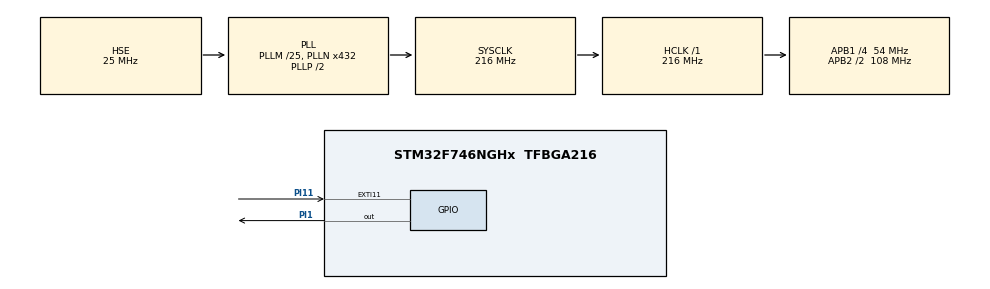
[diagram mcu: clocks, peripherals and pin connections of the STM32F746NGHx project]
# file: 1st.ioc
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Mcu.Family=STM32F7
Mcu.Name=STM32F746NGHx
Mcu.Package=TFBGA216
NVIC.EXTI15_10_IRQn=true\:3\:3\:true\:false\:true\:true\:true
NVIC.PriorityGroup=NVIC_PRIORITYGROUP_2
NVIC.TIM2_IRQn=true\:0\:0\:false\:false\:true\:true\:true
PA13.Mode=Trace_Asynchronous_SW
PA13.Signal=SYS_JTMS-SWDIO
PA14.Mode=Trace_Asynchronous_SW
PA14.Signal=SYS_JTCK-SWCLK
PB3.Mode=Trace_Asynchronous_SW
PB3.Signal=SYS_JTDO-SWO
PH0/OSC_IN.Mode=HSE-External-Oscillator
PH0/OSC_IN.Signal=RCC_OSC_IN
PH1/OSC_OUT.Mode=HSE-External-Oscillator
PH1/OSC_OUT.Signal=RCC_OSC_OUT
PI1.Signal=GPIO_Output
PI11.GPIO_PuPd=GPIO_PULLUP
PI11.Signal=GPXTI11
ProjectManager.HeapSize=0x200
ProjectManager.StackSize=0x400
ProjectManager.TargetToolchain=EWARM V8.32
RCC.AHBFreq_Value=216000000
RCC.APB1CLKDivider=RCC_HCLK_DIV4
RCC.APB1Freq_Value=54000000
RCC.APB1TimFreq_Value=108000000
RCC.APB2CLKDivider=RCC_HCLK_DIV2
RCC.APB2Freq_Value=108000000
RCC.APB2TimFreq_Value=216000000
RCC.CortexFreq_Value=216000000
RCC.HCLKFreq_Value=216000000
RCC.HSE_VALUE=25000000
RCC.HSI_VALUE=16000000
RCC.LSE_VALUE=32768
RCC.PLLM=25
RCC.PLLN=432
RCC.PLLSourceVirtual=RCC_PLLSOURCE_HSE
RCC.SYSCLKFreq_VALUE=216000000
RCC.SYSCLKSource=RCC_SYSCLKSOURCE_PLLCLK
RCC.USBFreq_Value=216000000
RCC.VCOOutputFreq_Value=432000000
TIM2.Period=10000-1
TIM2.Prescaler=10800-1
VP_TIM2_VS_ClockSourceINT.Mode=Internal
board=custom

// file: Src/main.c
/* USER CODE BEGIN Header */
/**
  ******************************************************************************
  * @file           : main.c
  * @brief          : Main program body
  ******************************************************************************
  * @attention
  *
  * <h2><center>&copy; Copyright (c) 2020 STMicroelectronics.
  * All rights reserved.</center></h2>
  *
  * This software component is licensed by ST under BSD 3-Clause license,
  * the "License"; You may not use this file except in compliance with the
  * License. You may obtain a copy of the License at:
  *                        opensource.org/licenses/BSD-3-Clause
  *
  ******************************************************************************
  */
/* USER CODE END Header */

#include "main.h"

TIM_HandleTypeDef htim2;

void SystemClock_Config(void);
static void MX_GPIO_Init(void);
static void MX_TIM2_Init(void);

/* USER CODE BEGIN 0 */
void HAL_GPIO_EXTI_Callback(uint16_t GPIO_Pin)
{
  if(HAL_GPIO_ReadPin(GPIOI,GPIO_PIN_11))
  {
      HAL_GPIO_TogglePin(GPIOI,GPIO_PIN_1);
  }
}
/* USER CODE END 0 */

int main(void)
{

  /* MCU Configuration--------------------------------------------------------*/

  /* Reset of all peripherals, Initializes the Flash interface and the Systick. */
  HAL_Init();

  /* Configure the system clock */
  SystemClock_Config();

  /* Initialize all configured peripherals */
  MX_GPIO_Init();
  MX_TIM2_Init();

  /* Infinite loop */
  while (1)
  {

  }
}

void SystemClock_Config(void)
{
  RCC_OscInitTypeDef RCC_OscInitStruct = {0};
  RCC_ClkInitTypeDef RCC_ClkInitStruct = {0};

  /** Configure the main internal regulator output voltage
  */
  __HAL_RCC_PWR_CLK_ENABLE();
  __HAL_PWR_VOLTAGESCALING_CONFIG(PWR_REGULATOR_VOLTAGE_SCALE1);
  /** Initializes the CPU, AHB and APB busses clocks
  */
  RCC_OscInitStruct.OscillatorType = RCC_OSCILLATORTYPE_HSE;
  RCC_OscInitStruct.HSEState = RCC_HSE_ON;
  RCC_OscInitStruct.PLL.PLLState = RCC_PLL_ON;
  RCC_OscInitStruct.PLL.PLLSource = RCC_PLLSOURCE_HSE;
  RCC_OscInitStruct.PLL.PLLM = 25;
  RCC_OscInitStruct.PLL.PLLN = 432;
  RCC_OscInitStruct.PLL.PLLP = RCC_PLLP_DIV2;
  RCC_OscInitStruct.PLL.PLLQ = 2;
  if (HAL_RCC_OscConfig(&RCC_OscInitStruct) != HAL_OK)
  {
    Error_Handler();
  }
  /** Activate the Over-Drive mode
  */
  if (HAL_PWREx_EnableOverDrive() != HAL_OK)
  {
    Error_Handler();
  }
  /** Initializes the CPU, AHB and APB busses clocks
  */
  RCC_ClkInitStruct.ClockType = RCC_CLOCKTYPE_HCLK|RCC_CLOCKTYPE_SYSCLK
                              |RCC_CLOCKTYPE_PCLK1|RCC_CLOCKTYPE_PCLK2;
  RCC_ClkInitStruct.SYSCLKSource = RCC_SYSCLKSOURCE_PLLCLK;
  RCC_ClkInitStruct.AHBCLKDivider = RCC_SYSCLK_DIV1;
  RCC_ClkInitStruct.APB1CLKDivider = RCC_HCLK_DIV4;
  RCC_ClkInitStruct.APB2CLKDivider = RCC_HCLK_DIV2;

  if (HAL_RCC_ClockConfig(&RCC_ClkInitStruct, FLASH_LATENCY_7) != HAL_OK)
  {
    Error_Handler();
  }
}

static void MX_TIM2_Init(void)
{

  TIM_ClockConfigTypeDef sClockSourceConfig = {0};
  TIM_MasterConfigTypeDef sMasterConfig = {0};

  htim2.Instance = TIM2;
  htim2.Init.Prescaler = 10800-1;
  htim2.Init.CounterMode = TIM_COUNTERMODE_UP;
  htim2.Init.Period = 10000-1;
  htim2.Init.ClockDivision = TIM_CLOCKDIVISION_DIV1;
  htim2.Init.AutoReloadPreload = TIM_AUTORELOAD_PRELOAD_DISABLE;
  if (HAL_TIM_Base_Init(&htim2) != HAL_OK)
  {
    Error_Handler();
  }
  sClockSourceConfig.ClockSource = TIM_CLOCKSOURCE_INTERNAL;
  if (HAL_TIM_ConfigClockSource(&htim2, &sClockSourceConfig) != HAL_OK)
  {
    Error_Handler();
  }
  sMasterConfig.MasterOutputTrigger = TIM_TRGO_RESET;
  sMasterConfig.MasterSlaveMode = TIM_MASTERSLAVEMODE_DISABLE;
  if (HAL_TIMEx_MasterConfigSynchronization(&htim2, &sMasterConfig) != HAL_OK)
  {
    Error_Handler();
  }

}

static void MX_GPIO_Init(void)
{
  GPIO_InitTypeDef GPIO_InitStruct = {0};

  /* GPIO Ports Clock Enable */
  __HAL_RCC_GPIOB_CLK_ENABLE();
  __HAL_RCC_GPIOA_CLK_ENABLE();
  __HAL_RCC_GPIOI_CLK_ENABLE();
  __HAL_RCC_GPIOH_CLK_ENABLE();

  /*Configure GPIO pin Output Level */
  HAL_GPIO_WritePin(GPIOI, GPIO_PIN_1, GPIO_PIN_RESET);

  /*Configure GPIO pin : PI1 */
  GPIO_InitStruct.Pin = GPIO_PIN_1;
  GPIO_InitStruct.Mode = GPIO_MODE_OUTPUT_PP;
  GPIO_InitStruct.Pull = GPIO_NOPULL;
  GPIO_InitStruct.Speed = GPIO_SPEED_FREQ_LOW;
  HAL_GPIO_Init(GPIOI, &GPIO_InitStruct);

  /*Configure GPIO pin : PI11 */
  GPIO_InitStruct.Pin = GPIO_PIN_11;
  GPIO_InitStruct.Mode = GPIO_MODE_IT_RISING;
  GPIO_InitStruct.Pull = GPIO_PULLUP;
  HAL_GPIO_Init(GPIOI, &GPIO_InitStruct);

  /* EXTI interrupt init*/
  HAL_NVIC_SetPriority(EXTI15_10_IRQn, 3, 3);
  HAL_NVIC_EnableIRQ(EXTI15_10_IRQn);

}

void Error_Handler(void)
{
}

/************************ (C) COPYRIGHT STMicroelectronics *****END OF FILE****/
